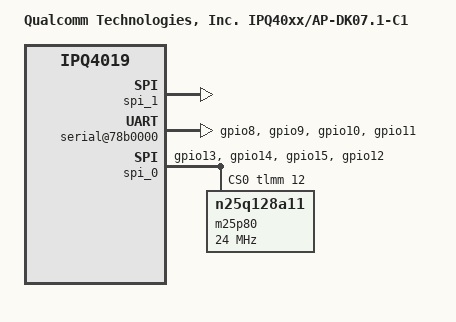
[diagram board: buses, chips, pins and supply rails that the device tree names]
// SPDX-License-Identifier: GPL-2.0
// Copyright (c) 2017, The Linux Foundation. All rights reserved.

#include "qcom-ipq4019-ap.dk07.1.dtsi"

/ {
	model = "Qualcomm Technologies, Inc. IPQ40xx/AP-DK07.1-C1";

	soc {
		spi_1: spi@78b6000 { /* BLSP1 QUP2 */
			status = "ok";
		};

		pinctrl@1000000 {
			serial_1_pins: serial1_pinmux {
				mux {
					pins = "gpio8", "gpio9",
						"gpio10", "gpio11";
					function = "blsp_uart1";
					bias-disable;
				};
			};

			spi_0_pins: spi_0_pinmux {
				pinmux {
					function = "blsp_spi0";
					pins = "gpio13", "gpio14", "gpio15";
					bias-disable;
				};
				pinmux_cs {
					function = "gpio";
					pins = "gpio12";
					bias-disable;
					output-high;
				};
			};
		};

		serial@78b0000 {
			pinctrl-0 = <&serial_1_pins>;
			pinctrl-names = "default";
			status = "ok";
		};

		spi_0: spi@78b5000 { /* BLSP1 QUP1 */
			pinctrl-0 = <&spi_0_pins>;
			pinctrl-names = "default";
			status = "ok";
			cs-gpios = <&tlmm 12 0>;

			m25p80@0 {
				#address-cells = <1>;
				#size-cells = <1>;
				reg = <0>;
				compatible = "n25q128a11";
				spi-max-frequency = <24000000>;
			};
		};
	};
};
